# nrf9230_radiocore register map
Vendor: Nordic Semiconductor; Series: nRF92; File version: 1
CPU: CM33 r0p4, little endian, MPU, FPU, 3 interrupt priority bits, 480 interrupts, 8 SAU regions
Registers are 32-bit, read-write, reset 0x0 unless marked. A register's access mark holds for its fields unless they carry their own. Offsets are from the block's base; [hi:lo] are bit positions; lines under a group give offsets from that group; {n}, {i} and the like mark numbered series; 'fields as' and 'values as' point back to an identical list.

## ECB030_NS — AES ECB Mode Encryption 0
Base 0x4303B000
Same registers: ECB031_NS 0x4303D000, ECB030_S 0x5303B000, ECB031_S 0x5303D000
0x00 TASKS_START wo — Start ECB block encrypt
  [0] TASKS_START
    1=Trigger task
0x04 TASKS_STOP wo — Abort a possible executing ECB operation
  [0] TASKS_STOP
    1=Trigger task
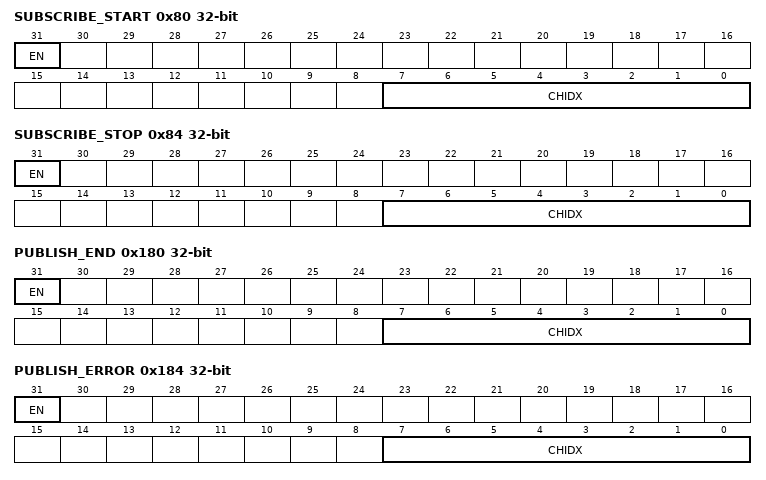
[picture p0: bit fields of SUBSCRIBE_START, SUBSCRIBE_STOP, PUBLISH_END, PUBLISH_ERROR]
0x80 SUBSCRIBE_START — Subscribe configuration for task START
  [31] EN
    0=Disabled (Disable subscription); 1=Enabled (Enable subscription)
  [7:0] CHIDX — DPPI channel that task START will subscribe to
0x84 SUBSCRIBE_STOP — Subscribe configuration for task STOP
  [31] EN
    values as SUBSCRIBE_START.EN
  [7:0] CHIDX — DPPI channel that task STOP will subscribe to
0x100 EVENTS_END — ECB block encrypt complete
  [0] EVENTS_END
    0=NotGenerated (Event not generated); 1=Generated (Event generated)
0x104 EVENTS_ERROR — ECB block encrypt aborted because of a STOP task or due to an error
  [0] EVENTS_ERROR
    values as EVENTS_END.EVENTS_END
0x180 PUBLISH_END — Publish configuration for event END
  [31] EN
    0=Disabled (Disable publishing); 1=Enabled (Enable publishing)
  [7:0] CHIDX — DPPI channel that event END will publish to
0x184 PUBLISH_ERROR — Publish configuration for event ERROR
  [31] EN
    values as PUBLISH_END.EN
  [7:0] CHIDX — DPPI channel that event ERROR will publish to
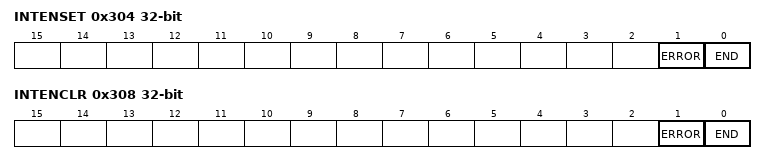
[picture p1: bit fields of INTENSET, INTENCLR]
0x304 INTENSET — Enable interrupt
  [1] ERROR — Write '1' to enable interrupt for event ERROR
    on read: 0=Disabled (Read: Disabled); 1=Enabled (Read: Enabled) | on write: 1=Set (Enable)
  [0] END — Write '1' to enable interrupt for event END
    values as ERROR
0x308 INTENCLR — Disable interrupt
  [1] ERROR — Write '1' to disable interrupt for event ERROR
    on read: 0=Disabled (Read: Disabled); 1=Enabled (Read: Enabled) | on write: 1=Clear (Disable)
  [0] END — Write '1' to disable interrupt for event END
    values as ERROR
0x400 ERRORSTATUS ro
  [2:0] ERRORSTATUS — Error status when the ERROR event is generated
    0=No errors have occurred; 1=PrematureInptrEnd (End of INPTR job list before data structure was read.); 2=PrematureOutptrEnd (End of OUTPTR job list before data structure was read.); 3=Aborted (Encryption aborted due to higher priority peripheral requesting or using the AES module.); 4=DmaError (Bus error during DMA access.)
0x510 KEY group — Unspecified
  {0x0+4j} VALUE[{j}] (j=0..3) wo — Description collection: 128-bit AES key
    [31:0] VALUE — AES 128-bit key value, bits (32*(n+1))-1 : (32*n)
0x530 IN group — IN EasyDMA channel
  0x00 PTR — Input pointer
    [31:0] PTR — Points to a job list containing unencrypted ECB data structure
0x538 OUT group — OUT EasyDMA channel
  0x00 PTR — Output pointer Points to a job list containing encrypted ECB data structure
    [31:0] PTR — Output pointer

## SWI0_NS — Software interrupt 0
Base 0x42058000
Same registers: SWI1_NS 0x42059000, SWI2_NS 0x4205A000, SWI3_NS 0x4205B000, SWI4_NS 0x4205C000, SWI5_NS 0x4205D000, SWI6_NS 0x4205E000, SWI7_NS 0x4205F000

## BELLBOARD_NS — BELLBOARD APB registers 0
Base 0x4F09B000
Same registers: BELLBOARD_S 0x5F09B000
{0x0+4i} TASKS_TRIGGER[{i}] (i=0..31) wo — Description collection: Task TRIGGER[n]
  [0] TASKS_TRIGGER — Task TRIGGER[n]
    1=Trigger task
{0x100+4i} EVENTS_TRIGGERED[{i}] (i=0..31) — Description collection: Event TRIGGERED[n]
  [0] EVENTS_TRIGGERED — Event TRIGGERED[n]
    0=NotGenerated (Event not generated); 1=Generated (Event generated)
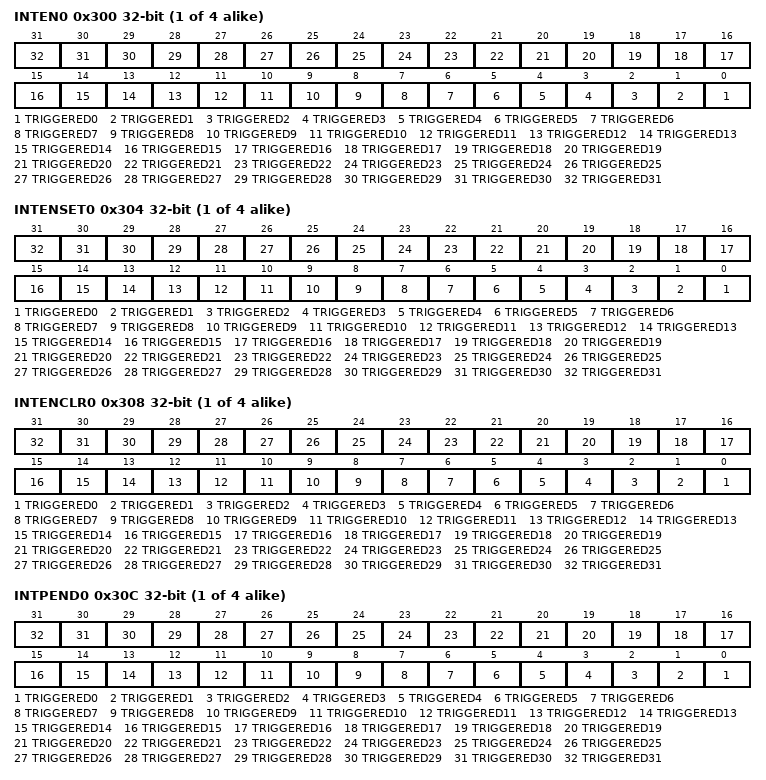
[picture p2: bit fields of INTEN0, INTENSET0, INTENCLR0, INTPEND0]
{0x300+0x10*i} INTEN{i} (i=0..3) — Enable or disable interrupt
  [all] fields
    0=Disabled; 1=Enabled
  [n] TRIGGERED{n} (n=0..31) — Enable or disable interrupt for event TRIGGERED[{n}]
{0x304+0x10*i} INTENSET{i} (i=0..3) — Enable interrupt
  [all] fields
    on read: 0=Disabled (Read: Disabled); 1=Enabled (Read: Enabled) | on write: 1=Set (Enable)
  [n] TRIGGERED{n} (n=0..31) — Write '1' to enable interrupt for event TRIGGERED[{n}]
{0x308+0x10*i} INTENCLR{i} (i=0..3) — Disable interrupt
  [all] fields
    on read: 0=Disabled (Read: Disabled); 1=Enabled (Read: Enabled) | on write: 1=Clear (Disable)
  [n] TRIGGERED{n} (n=0..31) — Write '1' to disable interrupt for event TRIGGERED[{n}]
{0x30C+0x10*i} INTPEND{i} ro (i=0..3) — Pending interrupts
  [all] fields
    on read: 0=NotPending (Read: Not pending); 1=Pending (Read: Pending)
  [n] TRIGGERED{n} (n=0..31) — Read pending status of interrupt for event TRIGGERED[{n}]
